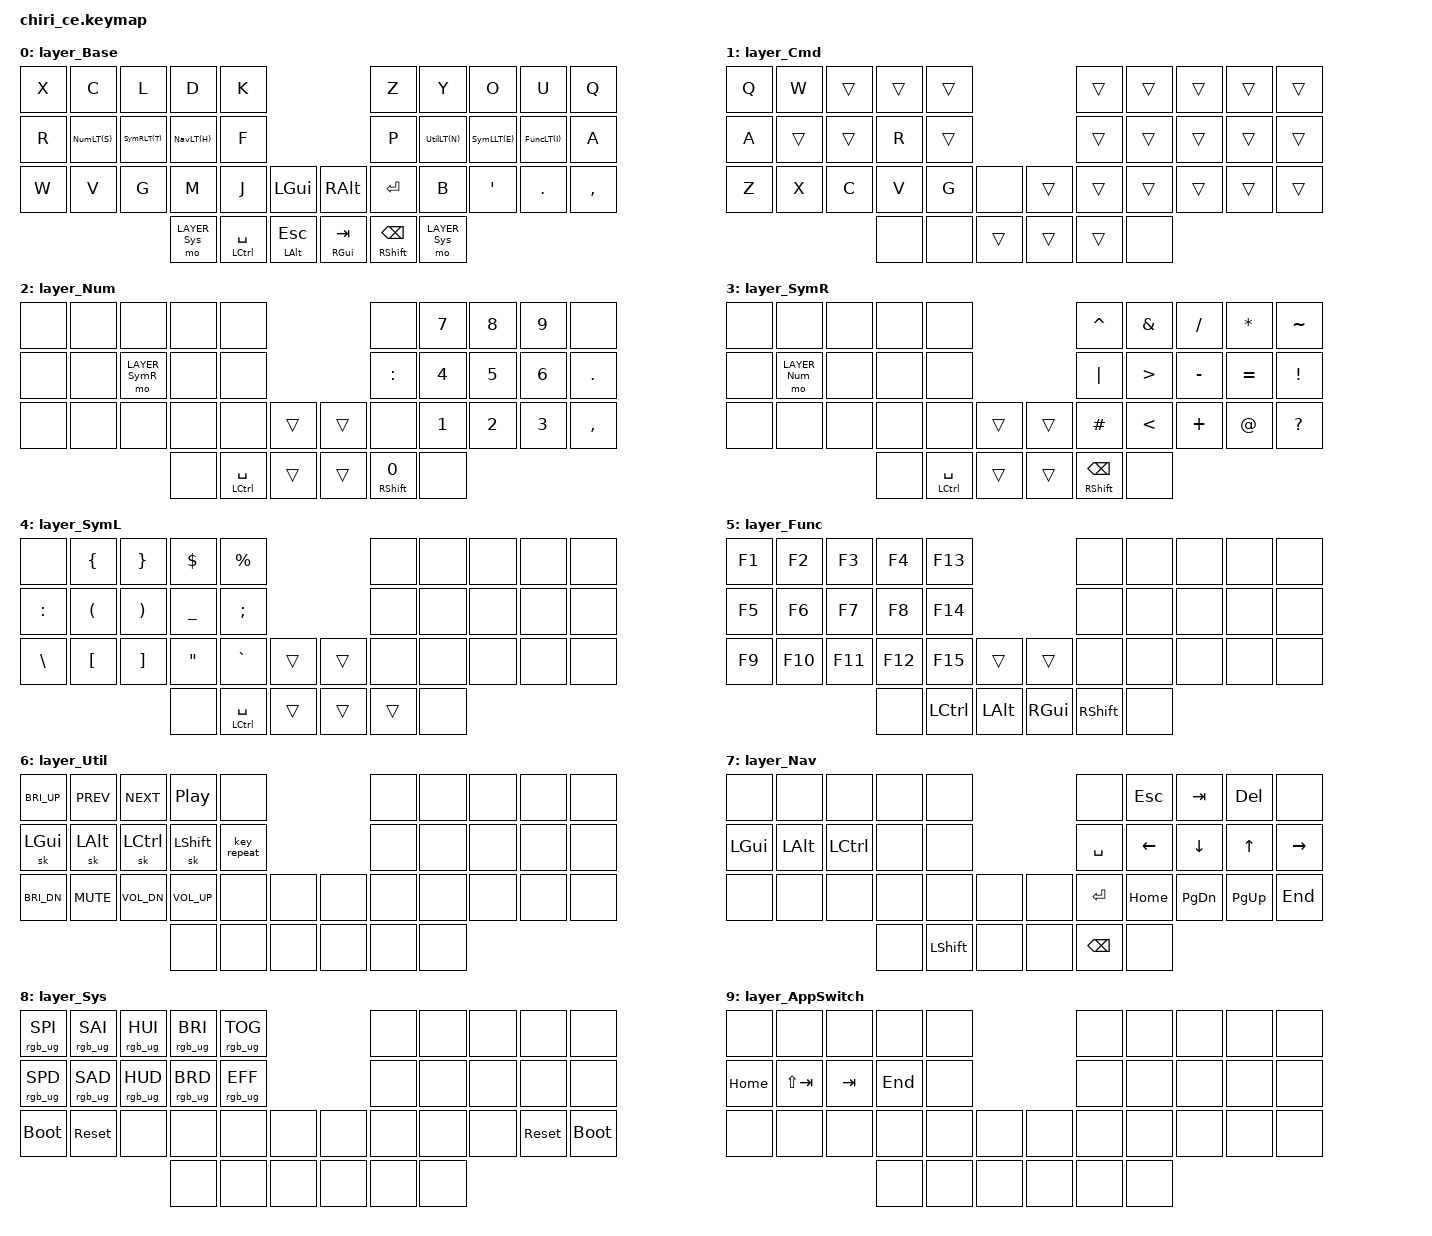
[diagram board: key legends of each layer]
#include <behaviors.dtsi>
#include <dt-bindings/zmk/keys.h>
#include <dt-bindings/zmk/rgb.h>

&led_strip {
    chain-length = <19>;
};

#define LAYER_Base 0
#define LAYER_Cmd 1
#define LAYER_Num 2
#define LAYER_SymR 3
#define LAYER_SymL 4
#define LAYER_Func 5
#define LAYER_Util 6
#define LAYER_Nav 7
#define LAYER_Sys 8
#define LAYER_AppSwitch 9

#define NumLT(x)  &lhlt LAYER_Num  x
#define SymRLT(x) &lhlt LAYER_SymR x
#define NavLT(x)  &lhlt LAYER_Nav  x
#define UtilLT(x) &rhlt LAYER_Util x
#define SymLLT(x) &rhlt LAYER_SymL x
#define FuncLT(x) &rhlt LAYER_Func x

/ {
    chosen {
        zmk,matrix-transform = &five_column_transform;
    };

    behaviors {
        tog_on: behavior_tog_on {
            compatible = "zmk,behavior-toggle-layer";
            #binding-cells = <1>;
            toggle-mode = "on";
        };
        tog_off: behavior_tog_off {
            compatible = "zmk,behavior-toggle-layer";
            #binding-cells = <1>;
            toggle-mode = "off";
        };

        // Enables the Command layer while held
        cmdt: cmdt {
            compatible = "zmk,behavior-hold-tap";
            #binding-cells = <2>;
            tapping-term-ms = <250>;
            bindings = <&macro_command_hold>, <&kp>;
            flavor = "balanced";
            require-prior-idle-ms = <150>;
        };

        // Left-hand home row layer-tap
        lhlt: lhlt {
            compatible = "zmk,behavior-hold-tap";
            #binding-cells = <2>;
            tapping-term-ms = <500>;
            bindings = <&mo>, <&kp>;
            flavor = "balanced";
            require-prior-idle-ms = <125>;
            hold-trigger-key-positions = <5 6 7 8 9 15 16 17 18 19 27 28 29 30 31 36>;
            hold-trigger-on-release;
        };

        // Right-hand home row layer-tap
        rhlt: rhlt {
            compatible = "zmk,behavior-hold-tap";
            #binding-cells = <2>;
            tapping-term-ms = <500>;
            bindings = <&mo>, <&kp>;
            flavor = "balanced";
            require-prior-idle-ms = <125>;
            hold-trigger-key-positions = <0 1 2 3 4 10 11 12 13 14 20 21 22 23 24>;
            hold-trigger-on-release;
        };

        // Quick-tap mod-tap
        qtmt: qtmt {
            compatible = "zmk,behavior-hold-tap";
            #binding-cells = <2>;
            tapping-term-ms = <200>;
            bindings = <&kp>, <&kp>;
            flavor = "balanced";
            quick-tap-ms = <200>;
        };
    };

    macros {
        // Enables the Command layer while a modifier is held
        macro_command_hold: macro_command_hold {
            label = "&MACRO_COMMAND_HOLD";
            compatible = "zmk,behavior-macro-one-param";
            #binding-cells = <1>;
            wait-ms = <0>;
            bindings = <&macro_press>
                , <&macro_param_1to1>
                , <&kp MACRO_PLACEHOLDER>
                , <&mo LAYER_Cmd>
                , <&macro_pause_for_release>
                , <&macro_release>
                , <&macro_param_1to1>
                , <&kp MACRO_PLACEHOLDER>
                , <&mo LAYER_Cmd>
                , <&macro_tap>
                , <&tog_off LAYER_AppSwitch>;
        };

        // Begins app switching, enabling the AppSwitch layer
        macro_app_switch_start: macro_app_switch_start {
            label = "&MACRO_APP_SWITCH_START";
            compatible = "zmk,behavior-macro";
            #binding-cells = <0>;
            wait-ms = <0>;
            bindings = <&tog_on LAYER_AppSwitch>
                , <&kp TAB>;
        };
    };

    combos {
        compatible = "zmk,combos";

        // Begins app switching
        combo_app_switch {
            timeout-ms = <75>;
            key-positions = <11 12>;
            bindings = <&macro_app_switch_start>;
            layers = <LAYER_Cmd>;
        };
    };

    keymap {
        compatible = "zmk,keymap";

        layer_Base {
            bindings = <
          &kp X    &kp C      &kp L     &kp D   &kp K                        &kp Z     &kp Y      &kp O      &kp U       &kp Q
          &kp R  NumLT(S)  SymRLT(T)  NavLT(H)  &kp F                        &kp P  UtilLT(N)  SymLLT(E)  FuncLT(I)      &kp A
          &kp W    &kp V      &kp G     &kp M   &kp J  &kp LGUI  &kp RALT  &kp RET     &kp B     &kp SQT    &kp DOT  &kp COMMA
               &mo LAYER_Sys  &cmdt LCTRL SPACE  &qtmt LALT ESC  &qtmt RGUI TAB  &qtmt RSHFT BSPC  &mo LAYER_Sys
            >;
        };

        layer_Cmd {
            bindings = <
  &kp Q   &kp W  &trans  &trans  &trans                   &trans  &trans    &trans    &trans  &trans
  &kp A  &trans  &trans   &kp R  &trans                   &trans  &trans    &trans    &trans  &trans
  &kp Z   &kp X   &kp C   &kp V   &kp G   &none  &trans   &trans  &trans    &trans    &trans  &trans
                          &none   &none  &trans  &trans   &trans   &none
            >;
        };

        layer_Num {
            bindings = <
  &none   &none            &none  &none   &none                      &none  &kp N7  &kp N8  &kp N9  &none
  &none   &none   &mo LAYER_SymR  &none   &none                  &kp COLON  &kp N4  &kp N5  &kp N6  &kp DOT
  &none   &none            &none  &none   &none   &trans  &trans     &none  &kp N1  &kp N2  &kp N3  &kp COMMA
                         &none  &mt LCTRL SPACE   &trans  &trans  &qtmt RSHFT N0  &none
            >;
        };

        layer_SymR {
            bindings = <
  &none           &none  &none   &none  &none                   &kp CARET  &kp AMPS   &kp FSLH   &kp STAR  &kp TILDE
  &none   &mo LAYER_Num  &none   &none  &none                    &kp PIPE    &kp GT  &kp MINUS  &kp EQUAL   &kp EXCL
  &none           &none  &none   &none  &none   &trans  &trans   &kp HASH    &kp LT   &kp PLUS     &kp AT  &kp QMARK
                       &none  &mt LCTRL SPACE   &trans  &trans  &qtmt RSHFT BSPC  &none
            >;
        };

        layer_SymL {
            bindings = <
      &none  &kp LBRC  &kp RBRC   &kp DLLR  &kp PRCNT                         &none   &none   &none   &none   &none
  &kp COLON  &kp LPAR  &kp RPAR  &kp UNDER   &kp SEMI                         &none   &none   &none   &none   &none
   &kp BSLH  &kp LBKT  &kp RBKT    &kp DQT  &kp GRAVE        &trans  &trans   &none   &none   &none   &none   &none
                                     &none  &mt LCTRL SPACE  &trans  &trans  &trans   &none
            >;
        };

        layer_Func {
            bindings = <
  &kp F1   &kp F2   &kp F3   &kp F4    &kp F13                           &none   &none   &none   &none   &none
  &kp F5   &kp F6   &kp F7   &kp F8    &kp F14                           &none   &none   &none   &none   &none
  &kp F9  &kp F10  &kp F11  &kp F12    &kp F15    &trans     &trans      &none   &none   &none   &none   &none
                              &none  &kp LCTRL  &kp LALT   &kp RGUI  &kp RSHFT   &none
            >;
        };

        layer_Util {
            bindings = <
  &kp C_BRI_UP  &kp C_PREV    &kp C_NEXT      &kp C_PP        &none                   &none   &none   &none   &none   &none
      &sk LGUI    &sk LALT     &sk LCTRL     &sk LSHFT  &key_repeat                   &none   &none   &none   &none   &none
  &kp C_BRI_DN  &kp C_MUTE  &kp C_VOL_DN  &kp C_VOL_UP        &none   &none   &none   &none   &none   &none   &none   &none
                                                 &none        &none   &none   &none   &none   &none
            >;
        };

        layer_Nav {
            bindings = <
      &none      &none        &none   &none   &none                        &none   &kp ESC    &kp TAB    &kp DEL      &none
   &kp LGUI   &kp LALT    &kp LCTRL   &none   &none                    &kp SPACE  &kp LEFT   &kp DOWN     &kp UP  &kp RIGHT
      &none      &none        &none   &none   &none      &none  &none    &kp RET  &kp HOME  &kp PG_DN  &kp PG_UP    &kp END
                                      &none   &kp LSHFT  &none  &none  &kp BSPC      &none
            >;
        };

        layer_Sys {
            bindings = <
  &rgb_ug RGB_SPI  &rgb_ug RGB_SAI  &rgb_ug RGB_HUI  &rgb_ug RGB_BRI  &rgb_ug RGB_TOG                   &none  &none  &none       &none        &none
  &rgb_ug RGB_SPD  &rgb_ug RGB_SAD  &rgb_ug RGB_HUD  &rgb_ug RGB_BRD  &rgb_ug RGB_EFF                   &none  &none  &none       &none        &none
      &bootloader       &sys_reset            &none            &none            &none   &none   &none   &none  &none  &none  &sys_reset  &bootloader
                                                               &none            &none   &none   &none   &none  &none
            >;
        };

        layer_AppSwitch {
            bindings = <
     &none        &none    &none    &none   &none                   &none     &none     &none   &none      &none
  &kp HOME  &kp LS(TAB)  &kp TAB  &kp END   &none                   &none     &none     &none   &none      &none
     &none        &none    &none    &none   &none   &none   &none   &none     &none     &none   &none      &none
                                    &none   &none   &none   &none   &none     &none
            >;
        };
    };
};

&lt {
    flavor = "balanced";
};

&mt {
    flavor = "balanced";
};

&sk {
    release-after-ms = <5000>;
    quick-release;
};
